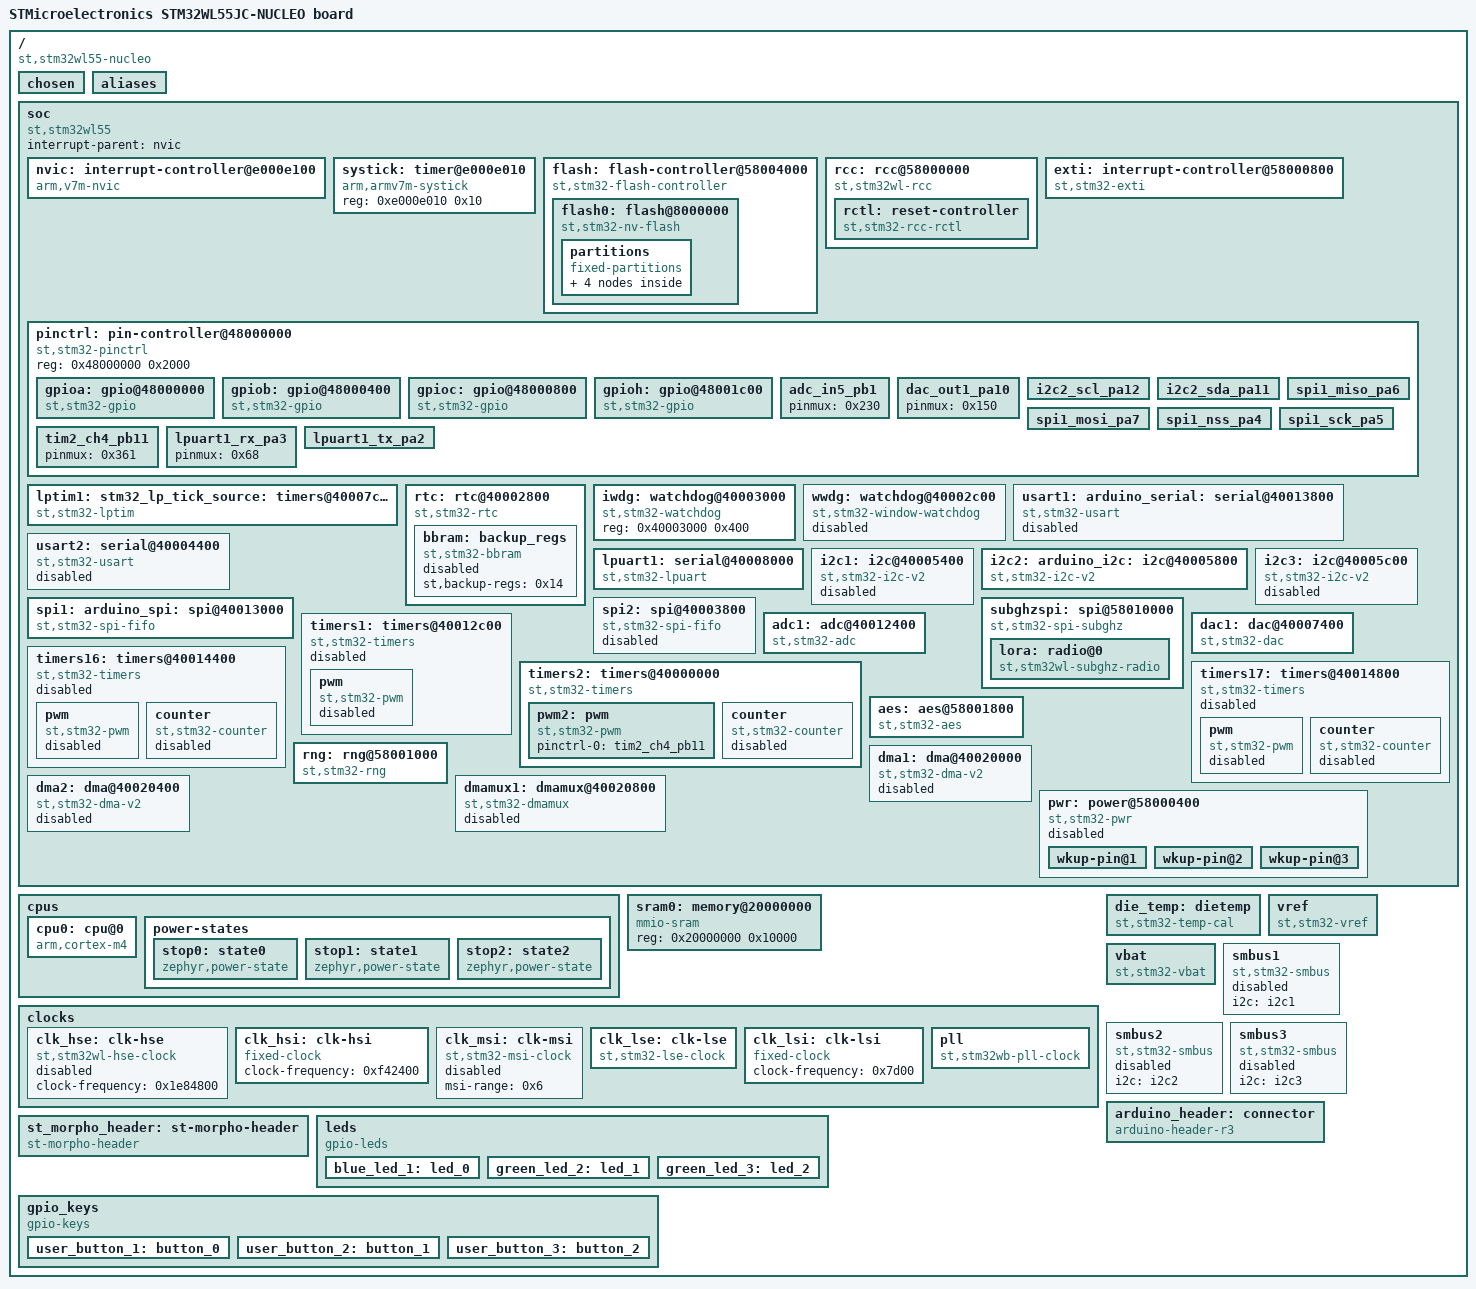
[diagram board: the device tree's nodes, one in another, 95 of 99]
/dts-v1/;

/ {
	#address-cells = < 0x1 >;
	#size-cells = < 0x1 >;
	model = "STMicroelectronics STM32WL55JC-NUCLEO board";
	compatible = "st,stm32wl55-nucleo";
	chosen {
		zephyr,entropy = &rng;
		zephyr,flash-controller = &flash;
		zephyr,console = &lpuart1;
		zephyr,shell-uart = &lpuart1;
		zephyr,sram = &sram0;
		zephyr,flash = &flash0;
		zephyr,code-partition = &slot0_partition;
	};
	aliases {
		led0 = &green_led_2;
		sw0 = &user_button_1;
		sw1 = &user_button_2;
		sw2 = &user_button_3;
		lora0 = &lora;
		watchdog0 = &iwdg;
		die-temp0 = &die_temp;
		volt-sensor0 = &vref;
		volt-sensor1 = &vbat;
	};
	soc {
		#address-cells = < 0x1 >;
		#size-cells = < 0x1 >;
		compatible = "st,stm32wl55", "st,stm32wl", "simple-bus";
		interrupt-parent = < &nvic >;
		ranges;
		nvic: interrupt-controller@e000e100 {
			#address-cells = < 0x1 >;
			compatible = "arm,v7m-nvic";
			reg = < 0xe000e100 0xc00 >;
			interrupt-controller;
			#interrupt-cells = < 0x2 >;
			arm,num-irq-priority-bits = < 0x4 >;
			phandle = < 0x1 >;
		};
		systick: timer@e000e010 {
			compatible = "arm,armv7m-systick";
			reg = < 0xe000e010 0x10 >;
		};
		flash: flash-controller@58004000 {
			compatible = "st,stm32-flash-controller", "st,stm32l4-flash-controller";
			reg = < 0x58004000 0x400 >;
			interrupts = < 0x4 0x0 >;
			#address-cells = < 0x1 >;
			#size-cells = < 0x1 >;
			flash0: flash@8000000 {
				compatible = "st,stm32-nv-flash", "soc-nv-flash";
				write-block-size = < 0x8 >;
				erase-block-size = < 0x800 >;
				max-erase-time = < 0x19 >;
				reg = < 0x8000000 0x40000 >;
				partitions {
					compatible = "fixed-partitions";
					#address-cells = < 0x1 >;
					#size-cells = < 0x1 >;
					boot_partition: partition@0 {
						label = "mcuboot";
						reg = < 0x0 0x8000 >;
						read-only;
					};
					slot0_partition: partition@8000 {
						label = "image-0";
						reg = < 0x8000 0x1a000 >;
					};
					slot1_partition: partition@22000 {
						label = "image-1";
						reg = < 0x22000 0x1a000 >;
					};
					storage_partition: partition@3c000 {
						label = "storage";
						reg = < 0x3c000 0x4000 >;
					};
				};
			};
		};
		rcc: rcc@58000000 {
			compatible = "st,stm32wl-rcc";
			#clock-cells = < 0x2 >;
			reg = < 0x58000000 0x400 >;
			clocks = < &pll >;
			clock-frequency = < 0x2dc6c00 >;
			cpu1-prescaler = < 0x1 >;
			cpu2-prescaler = < 0x1 >;
			ahb3-prescaler = < 0x1 >;
			apb1-prescaler = < 0x1 >;
			apb2-prescaler = < 0x1 >;
			phandle = < 0x3 >;
			rctl: reset-controller {
				compatible = "st,stm32-rcc-rctl";
				#reset-cells = < 0x1 >;
				phandle = < 0x4 >;
			};
		};
		exti: interrupt-controller@58000800 {
			compatible = "st,stm32-exti";
			interrupt-controller;
			#interrupt-cells = < 0x1 >;
			#address-cells = < 0x1 >;
			reg = < 0x58000800 0x400 >;
			num-lines = < 0x10 >;
			interrupts = < 0x6 0x0 >, < 0x7 0x0 >, < 0x8 0x0 >, < 0x9 0x0 >, < 0xa 0x0 >, < 0x16 0x0 >, < 0x29 0x0 >;
			interrupt-names = "line0", "line1", "line2", "line3", "line4", "line5-9", "line10-15";
			line-ranges = < 0x0 0x1 >, < 0x1 0x1 >, < 0x2 0x1 >, < 0x3 0x1 >, < 0x4 0x1 >, < 0x5 0x5 >, < 0xa 0x6 >;
		};
		pinctrl: pin-controller@48000000 {
			compatible = "st,stm32-pinctrl";
			#address-cells = < 0x1 >;
			#size-cells = < 0x1 >;
			reg = < 0x48000000 0x2000 >;
			gpioa: gpio@48000000 {
				compatible = "st,stm32-gpio";
				gpio-controller;
				#gpio-cells = < 0x2 >;
				reg = < 0x48000000 0x400 >;
				clocks = < &rcc 0x4c 0x1 >;
				phandle = < 0x11 >;
			};
			gpiob: gpio@48000400 {
				compatible = "st,stm32-gpio";
				gpio-controller;
				#gpio-cells = < 0x2 >;
				reg = < 0x48000400 0x400 >;
				clocks = < &rcc 0x4c 0x2 >;
				phandle = < 0x12 >;
			};
			gpioc: gpio@48000800 {
				compatible = "st,stm32-gpio";
				gpio-controller;
				#gpio-cells = < 0x2 >;
				reg = < 0x48000800 0x400 >;
				clocks = < &rcc 0x4c 0x4 >;
				phandle = < 0xd >;
			};
			gpioh: gpio@48001c00 {
				compatible = "st,stm32-gpio";
				gpio-controller;
				#gpio-cells = < 0x2 >;
				reg = < 0x48001c00 0x400 >;
				clocks = < &rcc 0x4c 0x80 >;
				phandle = < 0x1b >;
			};
			adc_in5_pb1: adc_in5_pb1 {
				pinmux = < 0x230 >;
				phandle = < 0xe >;
			};
			dac_out1_pa10: dac_out1_pa10 {
				pinmux = < 0x150 >;
				phandle = < 0xf >;
			};
			i2c2_scl_pa12: i2c2_scl_pa12 {
				pinmux = < 0x184 >;
				bias-pull-up;
				drive-open-drain;
				phandle = < 0x7 >;
			};
			i2c2_sda_pa11: i2c2_sda_pa11 {
				pinmux = < 0x164 >;
				bias-pull-up;
				drive-open-drain;
				phandle = < 0x8 >;
			};
			spi1_miso_pa6: spi1_miso_pa6 {
				pinmux = < 0xc5 >;
				bias-pull-down;
				phandle = < 0xb >;
			};
			spi1_mosi_pa7: spi1_mosi_pa7 {
				pinmux = < 0xe5 >;
				bias-pull-down;
				phandle = < 0xc >;
			};
			spi1_nss_pa4: spi1_nss_pa4 {
				pinmux = < 0x85 >;
				bias-pull-up;
				phandle = < 0x9 >;
			};
			spi1_sck_pa5: spi1_sck_pa5 {
				pinmux = < 0xa5 >;
				bias-pull-down;
				slew-rate = "very-high-speed";
				phandle = < 0xa >;
			};
			tim2_ch4_pb11: tim2_ch4_pb11 {
				pinmux = < 0x361 >;
				phandle = < 0x10 >;
			};
			lpuart1_rx_pa3: lpuart1_rx_pa3 {
				pinmux = < 0x68 >;
				phandle = < 0x6 >;
			};
			lpuart1_tx_pa2: lpuart1_tx_pa2 {
				pinmux = < 0x48 >;
				bias-pull-up;
				phandle = < 0x5 >;
			};
		};
		lptim1: stm32_lp_tick_source: timers@40007c00 {
			compatible = "st,stm32-lptim";
			clocks = < &rcc 0x58 0x80000000 >, < &rcc 0x3 0x17288 >;
			#address-cells = < 0x1 >;
			#size-cells = < 0x0 >;
			reg = < 0x40007c00 0x400 >;
			interrupts = < 0x27 0x1 >;
			interrupt-names = "wakeup";
			status = "okay";
		};
		rtc: rtc@40002800 {
			compatible = "st,stm32-rtc";
			reg = < 0x40002800 0x400 >;
			interrupts = < 0x2a 0x0 >;
			clocks = < &rcc 0x58 0x400 >, < &rcc 0x2 0x16890 >;
			prescaler = < 0x8000 >;
			alarms-count = < 0x2 >;
			alrm-exti-line = < 0x11 >;
			status = "okay";
			bbram: backup_regs {
				compatible = "st,stm32-bbram";
				st,backup-regs = < 0x14 >;
				status = "disabled";
			};
		};
		iwdg: watchdog@40003000 {
			compatible = "st,stm32-watchdog";
			reg = < 0x40003000 0x400 >;
			status = "okay";
		};
		wwdg: watchdog@40002c00 {
			compatible = "st,stm32-window-watchdog";
			reg = < 0x40002c00 0x400 >;
			clocks = < &rcc 0x58 0x800 >;
			interrupts = < 0x0 0x7 >;
			status = "disabled";
		};
		usart1: arduino_serial: serial@40013800 {
			compatible = "st,stm32-usart", "st,stm32-uart";
			reg = < 0x40013800 0x400 >;
			clocks = < &rcc 0x60 0x4000 >;
			resets = < &rctl 0x80e >;
			interrupts = < 0x24 0x0 >;
			status = "disabled";
		};
		usart2: serial@40004400 {
			compatible = "st,stm32-usart", "st,stm32-uart";
			reg = < 0x40004400 0x400 >;
			clocks = < &rcc 0x58 0x20000 >;
			resets = < &rctl 0x711 >;
			interrupts = < 0x25 0x0 >;
			status = "disabled";
		};
		lpuart1: serial@40008000 {
			compatible = "st,stm32-lpuart", "st,stm32-uart";
			reg = < 0x40008000 0x400 >;
			clocks = < &rcc 0x5c 0x1 >;
			resets = < &rctl 0x780 >;
			interrupts = < 0x26 0x0 >;
			wakeup-line = < 0x1c >;
			status = "okay";
			pinctrl-0 = < &lpuart1_tx_pa2 &lpuart1_rx_pa3 >;
			pinctrl-names = "default";
			current-speed = < 0x1c200 >;
		};
		i2c1: i2c@40005400 {
			compatible = "st,stm32-i2c-v2";
			clock-frequency = < 0x186a0 >;
			#address-cells = < 0x1 >;
			#size-cells = < 0x0 >;
			reg = < 0x40005400 0x400 >;
			clocks = < &rcc 0x58 0x200000 >;
			interrupts = < 0x1e 0x0 >, < 0x1f 0x0 >;
			interrupt-names = "event", "error";
			status = "disabled";
			phandle = < 0x18 >;
		};
		i2c2: arduino_i2c: i2c@40005800 {
			compatible = "st,stm32-i2c-v2";
			clock-frequency = < 0x61a80 >;
			#address-cells = < 0x1 >;
			#size-cells = < 0x0 >;
			reg = < 0x40005800 0x400 >;
			clocks = < &rcc 0x58 0x400000 >;
			interrupts = < 0x20 0x0 >, < 0x21 0x0 >;
			interrupt-names = "event", "error";
			status = "okay";
			pinctrl-0 = < &i2c2_scl_pa12 &i2c2_sda_pa11 >;
			pinctrl-names = "default";
			phandle = < 0x19 >;
		};
		i2c3: i2c@40005c00 {
			compatible = "st,stm32-i2c-v2";
			clock-frequency = < 0x186a0 >;
			#address-cells = < 0x1 >;
			#size-cells = < 0x0 >;
			reg = < 0x40005c00 0x400 >;
			clocks = < &rcc 0x58 0x800000 >;
			interrupts = < 0x30 0x0 >, < 0x31 0x0 >;
			interrupt-names = "event", "error";
			status = "disabled";
			phandle = < 0x1a >;
		};
		spi1: arduino_spi: spi@40013000 {
			compatible = "st,stm32-spi-fifo", "st,stm32-spi";
			#address-cells = < 0x1 >;
			#size-cells = < 0x0 >;
			reg = < 0x40013000 0x400 >;
			interrupts = < 0x22 0x5 >;
			clocks = < &rcc 0x60 0x1000 >;
			status = "okay";
			pinctrl-0 = < &spi1_nss_pa4 &spi1_sck_pa5 &spi1_miso_pa6 &spi1_mosi_pa7 >;
			pinctrl-names = "default";
		};
		spi2: spi@40003800 {
			compatible = "st,stm32-spi-fifo", "st,stm32-spi";
			#address-cells = < 0x1 >;
			#size-cells = < 0x0 >;
			reg = < 0x40003800 0x400 >;
			interrupts = < 0x23 0x5 >;
			clocks = < &rcc 0x58 0x4000 >;
			status = "disabled";
		};
		subghzspi: spi@58010000 {
			compatible = "st,stm32-spi-subghz", "st,stm32-spi-fifo", "st,stm32-spi";
			#address-cells = < 0x1 >;
			#size-cells = < 0x0 >;
			reg = < 0x58010000 0x400 >;
			interrupts = < 0x2c 0x5 >;
			clocks = < &rcc 0x64 0x1 >;
			status = "okay";
			use-subghzspi-nss;
			lora: radio@0 {
				compatible = "st,stm32wl-subghz-radio";
				reg = < 0x0 >;
				interrupts = < 0x32 0x0 >;
				spi-max-frequency = < 0x7a1200 >;
				status = "okay";
				tx-enable-gpios = < &gpioc 0x4 0x1 >;
				rx-enable-gpios = < &gpioc 0x5 0x1 >;
				dio3-tcxo-voltage = < 0x1 >;
				tcxo-power-startup-delay-ms = < 0x5 >;
				power-amplifier-output = "rfo-hp";
				rfo-lp-max-power = < 0xf >;
				rfo-hp-max-power = < 0x16 >;
			};
		};
		adc1: adc@40012400 {
			compatible = "st,stm32-adc";
			reg = < 0x40012400 0x400 >;
			clocks = < &rcc 0x60 0x200 >;
			interrupts = < 0x12 0x0 >;
			status = "okay";
			#io-channel-cells = < 0x1 >;
			resolutions = < 0x60630c 0x51630c 0x42630c 0x33630c >;
			sampling-times = < 0x2 0x4 0x8 0xd 0x14 0x28 0x50 0xa1 >;
			num-sampling-time-common-channels = < 0x2 >;
			st,adc-sequencer = < 0x0 >;
			pinctrl-0 = < &adc_in5_pb1 >;
			pinctrl-names = "default";
			st,adc-clock-source = < 0x1 >;
			st,adc-prescaler = < 0x4 >;
			phandle = < 0x17 >;
		};
		dac1: dac@40007400 {
			compatible = "st,stm32-dac";
			reg = < 0x40007400 0x400 >;
			clocks = < &rcc 0x58 0x20000000 >;
			status = "okay";
			#io-channel-cells = < 0x1 >;
			pinctrl-0 = < &dac_out1_pa10 >;
			pinctrl-names = "default";
		};
		timers1: timers@40012c00 {
			compatible = "st,stm32-timers";
			reg = < 0x40012c00 0x400 >;
			clocks = < &rcc 0x60 0x800 >;
			resets = < &rctl 0x80b >;
			interrupts = < 0x17 0x0 >, < 0x18 0x0 >, < 0x19 0x0 >, < 0x1a 0x0 >;
			interrupt-names = "brk", "up", "trgcom", "cc";
			st,prescaler = < 0x0 >;
			status = "disabled";
			pwm {
				compatible = "st,stm32-pwm";
				status = "disabled";
				#pwm-cells = < 0x3 >;
			};
		};
		timers2: timers@40000000 {
			compatible = "st,stm32-timers";
			reg = < 0x40000000 0x400 >;
			clocks = < &rcc 0x58 0x1 >;
			resets = < &rctl 0x700 >;
			interrupts = < 0x1b 0x0 >;
			interrupt-names = "global";
			st,prescaler = < 0x0 >;
			status = "okay";
			pwm2: pwm {
				compatible = "st,stm32-pwm";
				status = "okay";
				#pwm-cells = < 0x3 >;
				pinctrl-0 = < &tim2_ch4_pb11 >;
				pinctrl-names = "default";
			};
			counter {
				compatible = "st,stm32-counter";
				status = "disabled";
			};
		};
		timers16: timers@40014400 {
			compatible = "st,stm32-timers";
			reg = < 0x40014400 0x400 >;
			clocks = < &rcc 0x60 0x20000 >;
			resets = < &rctl 0x811 >;
			interrupts = < 0x1c 0x0 >;
			interrupt-names = "global";
			st,prescaler = < 0x0 >;
			status = "disabled";
			pwm {
				compatible = "st,stm32-pwm";
				status = "disabled";
				#pwm-cells = < 0x3 >;
			};
			counter {
				compatible = "st,stm32-counter";
				status = "disabled";
			};
		};
		timers17: timers@40014800 {
			compatible = "st,stm32-timers";
			reg = < 0x40014800 0x400 >;
			clocks = < &rcc 0x60 0x40000 >;
			resets = < &rctl 0x812 >;
			interrupts = < 0x1d 0x0 >;
			interrupt-names = "global";
			st,prescaler = < 0x0 >;
			status = "disabled";
			pwm {
				compatible = "st,stm32-pwm";
				status = "disabled";
				#pwm-cells = < 0x3 >;
			};
			counter {
				compatible = "st,stm32-counter";
				status = "disabled";
			};
		};
		aes: aes@58001800 {
			compatible = "st,stm32-aes";
			reg = < 0x58001800 0x400 >;
			clocks = < &rcc 0x50 0x20000 >;
			interrupts = < 0x33 0x0 >;
			status = "okay";
		};
		rng: rng@58001000 {
			compatible = "st,stm32-rng";
			reg = < 0x58001000 0x400 >;
			interrupts = < 0x34 0x0 >;
			clocks = < &rcc 0x50 0x40000 >;
			health-test-magic = < 0x17590abc >;
			health-test-config = < 0xaa74 >;
			status = "okay";
		};
		dma1: dma@40020000 {
			compatible = "st,stm32-dma-v2";
			#dma-cells = < 0x3 >;
			reg = < 0x40020000 0x400 >;
			interrupts = < 0xb 0x0 0xc 0x0 0xd 0x0 0xe 0x0 0xf 0x0 0x10 0x0 0x11 0x0 >;
			clocks = < &rcc 0x48 0x1 >;
			dma-requests = < 0x7 >;
			dma-offset = < 0x0 >;
			status = "disabled";
		};
		dma2: dma@40020400 {
			compatible = "st,stm32-dma-v2";
			#dma-cells = < 0x3 >;
			reg = < 0x40020400 0x400 >;
			interrupts = < 0x36 0x0 0x37 0x0 0x38 0x0 0x39 0x0 0x3a 0x0 0x3b 0x0 0x3c 0x0 >;
			clocks = < &rcc 0x48 0x2 >;
			dma-requests = < 0x7 >;
			dma-offset = < 0x7 >;
			status = "disabled";
		};
		dmamux1: dmamux@40020800 {
			compatible = "st,stm32-dmamux";
			#dma-cells = < 0x3 >;
			reg = < 0x40020800 0x400 >;
			interrupts = < 0x3d 0x0 >;
			clocks = < &rcc 0x48 0x4 >;
			dma-channels = < 0xe >;
			dma-generators = < 0x4 >;
			dma-requests = < 0x26 >;
			status = "disabled";
		};
		pwr: power@58000400 {
			compatible = "st,stm32-pwr";
			reg = < 0x58000400 0x400 >;
			status = "disabled";
			wkup-pins-nb = < 0x3 >;
			wkup-pins-pol;
			wkup-pins-pupd;
			#address-cells = < 0x1 >;
			#size-cells = < 0x0 >;
			wkup-pin@1 {
				reg = < 0x1 >;
				wkup-gpios = < &gpioa 0x0 0x0 >;
			};
			wkup-pin@2 {
				reg = < 0x2 >;
				wkup-gpios = < &gpioc 0xd 0x0 >;
			};
			wkup-pin@3 {
				reg = < 0x3 >;
				wkup-gpios = < &gpiob 0x3 0x0 >;
			};
		};
	};
	cpus {
		#address-cells = < 0x1 >;
		#size-cells = < 0x0 >;
		cpu0: cpu@0 {
			device_type = "cpu";
			compatible = "arm,cortex-m4";
			reg = < 0x0 >;
			cpu-power-states = < &stop0 &stop1 &stop2 >;
		};
		power-states {
			stop0: state0 {
				compatible = "zephyr,power-state";
				power-state-name = "suspend-to-idle";
				substate-id = < 0x1 >;
				min-residency-us = < 0x64 >;
				phandle = < 0x13 >;
			};
			stop1: state1 {
				compatible = "zephyr,power-state";
				power-state-name = "suspend-to-idle";
				substate-id = < 0x2 >;
				min-residency-us = < 0x1f4 >;
				phandle = < 0x14 >;
			};
			stop2: state2 {
				compatible = "zephyr,power-state";
				power-state-name = "suspend-to-idle";
				substate-id = < 0x3 >;
				min-residency-us = < 0x384 >;
				phandle = < 0x15 >;
			};
		};
	};
	sram0: memory@20000000 {
		compatible = "mmio-sram";
		reg = < 0x20000000 0x10000 >;
	};
	clocks {
		clk_hse: clk-hse {
			#clock-cells = < 0x0 >;
			compatible = "st,stm32wl-hse-clock";
			clock-frequency = < 0x1e84800 >;
			status = "disabled";
		};
		clk_hsi: clk-hsi {
			#clock-cells = < 0x0 >;
			compatible = "fixed-clock";
			clock-frequency = < 0xf42400 >;
			status = "okay";
			phandle = < 0x16 >;
		};
		clk_msi: clk-msi {
			#clock-cells = < 0x0 >;
			compatible = "st,stm32-msi-clock";
			msi-range = < 0x6 >;
			status = "disabled";
		};
		clk_lse: clk-lse {
			#clock-cells = < 0x0 >;
			compatible = "st,stm32-lse-clock";
			clock-frequency = < 0x8000 >;
			driving-capability = < 0x0 >;
			status = "okay";
		};
		clk_lsi: clk-lsi {
			#clock-cells = < 0x0 >;
			compatible = "fixed-clock";
			clock-frequency = < 0x7d00 >;
			status = "okay";
		};
		pll: pll {
			#clock-cells = < 0x0 >;
			compatible = "st,stm32wb-pll-clock";
			status = "okay";
			div-m = < 0x1 >;
			mul-n = < 0x6 >;
			div-r = < 0x2 >;
			div-q = < 0x2 >;
			clocks = < &clk_hsi >;
			phandle = < 0x2 >;
		};
	};
	die_temp: dietemp {
		compatible = "st,stm32-temp-cal";
		ts-cal1-addr = < 0x1fff75a8 >;
		ts-cal2-addr = < 0x1fff75c8 >;
		ts-cal1-temp = < 0x1e >;
		ts-cal2-temp = < 0x82 >;
		ts-cal-vrefanalog = < 0xce4 >;
		io-channels = < &adc1 0xc >;
		status = "okay";
	};
	vref: vref {
		compatible = "st,stm32-vref";
		vrefint-cal-addr = < 0x1fff75aa >;
		vrefint-cal-mv = < 0xce4 >;
		io-channels = < &adc1 0xd >;
		status = "okay";
	};
	vbat: vbat {
		compatible = "st,stm32-vbat";
		ratio = < 0x3 >;
		io-channels = < &adc1 0xe >;
		status = "okay";
	};
	smbus1: smbus1 {
		compatible = "st,stm32-smbus";
		#address-cells = < 0x1 >;
		#size-cells = < 0x0 >;
		i2c = < &i2c1 >;
		status = "disabled";
	};
	smbus2: smbus2 {
		compatible = "st,stm32-smbus";
		#address-cells = < 0x1 >;
		#size-cells = < 0x0 >;
		i2c = < &i2c2 >;
		status = "disabled";
	};
	smbus3: smbus3 {
		compatible = "st,stm32-smbus";
		#address-cells = < 0x1 >;
		#size-cells = < 0x0 >;
		i2c = < &i2c3 >;
		status = "disabled";
	};
	arduino_header: connector {
		compatible = "arduino-header-r3";
		#gpio-cells = < 0x2 >;
		gpio-map-mask = < 0xffffffff 0xffffffc0 >;
		gpio-map-pass-thru = < 0x0 0x3f >;
		gpio-map = < 0x0 0x0 &gpiob 0x1 0x0 >, < 0x1 0x0 &gpiob 0x2 0x0 >, < 0x2 0x0 &gpioa 0xa 0x0 >, < 0x3 0x0 &gpiob 0x4 0x0 >, < 0x4 0x0 &gpiob 0xe 0x0 >, < 0x5 0x0 &gpiob 0xd 0x0 >, < 0x6 0x0 &gpiob 0x7 0x0 >, < 0x7 0x0 &gpiob 0x6 0x0 >, < 0x8 0x0 &gpiob 0xc 0x0 >, < 0x9 0x0 &gpiob 0x3 0x0 >, < 0xa 0x0 &gpiob 0x5 0x0 >, < 0xb 0x0 &gpiob 0x8 0x0 >, < 0xc 0x0 &gpiob 0xa 0x0 >, < 0xd 0x0 &gpioc 0x1 0x0 >, < 0xe 0x0 &gpioc 0x2 0x0 >, < 0xf 0x0 &gpioa 0x9 0x0 >, < 0x10 0x0 &gpioa 0x4 0x0 >, < 0x11 0x0 &gpioa 0x7 0x0 >, < 0x12 0x0 &gpioa 0x6 0x0 >, < 0x13 0x0 &gpioa 0x5 0x0 >, < 0x14 0x0 &gpiob 0xb 0x0 >, < 0x15 0x0 &gpiob 0xc 0x0 >;
	};
	st_morpho_header: st-morpho-header {
		compatible = "st-morpho-header";
		#gpio-cells = < 0x2 >;
		gpio-map-mask = < 0xff 0x0 >;
		gpio-map-pass-thru = < 0x0 0x3f >;
		gpio-map = < 0x6 0x0 &gpioh 0x3 0x0 >, < 0xc 0x0 &gpioa 0xd 0x0 >, < 0xe 0x0 &gpioa 0xe 0x0 >, < 0x10 0x0 &gpioa 0xf 0x0 >, < 0x16 0x0 &gpioc 0xd 0x0 >, < 0x18 0x0 &gpioc 0xe 0x0 >, < 0x1a 0x0 &gpioc 0xf 0x0 >, < 0x1b 0x0 &gpiob 0x1 0x0 >, < 0x1d 0x0 &gpiob 0x2 0x0 >, < 0x1f 0x0 &gpioa 0xa 0x0 >, < 0x21 0x0 &gpiob 0x4 0x0 >, < 0x23 0x0 &gpiob 0xe 0x0 >, < 0x25 0x0 &gpiob 0xd 0x0 >, < 0x48 0x0 &gpioa 0x0 0x0 >, < 0x49 0x0 &gpioc 0x4 0x0 >, < 0x4a 0x0 &gpioa 0xc 0x0 >, < 0x4b 0x0 &gpioc 0x5 0x0 >, < 0x4c 0x0 &gpioa 0xb 0x0 >, < 0x52 0x0 &gpioa 0x5 0x0 >, < 0x53 0x0 &gpioc 0x6 0x0 >, < 0x54 0x0 &gpioa 0x6 0x0 >, < 0x55 0x0 &gpioc 0x0 0x0 >, < 0x56 0x0 &gpioa 0x7 0x0 >, < 0x57 0x0 &gpioa 0x8 0x0 >, < 0x58 0x0 &gpioa 0x4 0x0 >, < 0x5a 0x0 &gpioa 0x9 0x0 >, < 0x5c 0x0 &gpioc 0x2 0x0 >, < 0x5d 0x0 &gpiob 0x0 0x0 >, < 0x5e 0x0 &gpioc 0x1 0x0 >, < 0x60 0x0 &gpiob 0xa 0x0 >, < 0x61 0x0 &gpiob 0x9 0x0 >, < 0x62 0x0 &gpiob 0x8 0x0 >, < 0x63 0x0 &gpiob 0xf 0x0 >, < 0x64 0x0 &gpiob 0x5 0x0 >, < 0x65 0x0 &gpiob 0xb 0x0 >, < 0x66 0x0 &gpiob 0x3 0x0 >, < 0x68 0x0 &gpiob 0xc 0x0 >, < 0x6a 0x0 &gpiob 0x6 0x0 >, < 0x6b 0x0 &gpioa 0x1 0x0 >, < 0x6c 0x0 &gpiob 0x7 0x0 >, < 0x6d 0x0 &gpioc 0x3 0x0 >;
	};
	leds: leds {
		compatible = "gpio-leds";
		blue_led_1: led_0 {
			gpios = < &gpiob 0xf 0x0 >;
			label = "User LED1";
		};
		green_led_2: led_1 {
			gpios = < &gpiob 0x9 0x0 >;
			label = "User LED2";
		};
		green_led_3: led_2 {
			gpios = < &gpiob 0xb 0x0 >;
			label = "User LED3";
		};
	};
	gpio_keys {
		compatible = "gpio-keys";
		user_button_1: button_0 {
			label = "SW1";
			gpios = < &gpioa 0x0 0x11 >;
			zephyr,code = < 0xb >;
		};
		user_button_2: button_1 {
			label = "SW2";
			gpios = < &gpioa 0x1 0x11 >;
			zephyr,code = < 0x2 >;
		};
		user_button_3: button_2 {
			label = "SW3";
			gpios = < &gpioc 0x6 0x11 >;
			zephyr,code = < 0x3 >;
		};
	};
};
